AUTOSAR XML (schema 00049)
package /SwComponentTypes
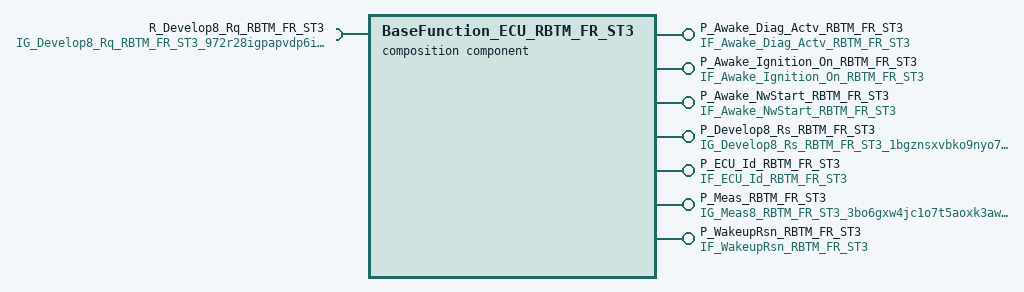
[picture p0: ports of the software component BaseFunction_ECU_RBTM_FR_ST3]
  composition sw component type BaseFunction_ECU_RBTM_FR_ST3  # Base Function
    7 x provide port:
      P_Awake_Diag_Actv_RBTM_FR_ST3: nonqueued-sender-com-spec{data-element=Awake_Diag_Actv_RBTM_FR_ST3, init-value=constant-reference=XDIS_h5tcyk98kzbgrc5svasomeyt}, provided-interface=IF_Awake_Diag_Actv_RBTM_FR_ST3  # Wachhalten für Diagnose aktiv / Stay awake for diagnostics active
      P_Awake_Ignition_On_RBTM_FR_ST3: nonqueued-sender-com-spec{data-element=Awake_Ignition_On_RBTM_FR_ST3, init-value=constant-reference=XDIS_h5tcyk98kzbgrc5svasomeyt}, provided-interface=IF_Awake_Ignition_On_RBTM_FR_ST3  # Wachhalten für Zündung eingeschaltet / Stay awake for ignition on
      P_Awake_NwStart_RBTM_FR_ST3: nonqueued-sender-com-spec{data-element=Awake_NwStart_RBTM_FR_ST3, init-value=constant-reference=XDIS_h5tcyk98kzbgrc5svasomeyt}, provided-interface=IF_Awake_NwStart_RBTM_FR_ST3  # Wachhalten für Netzwerkstartphase / Stay awake for network startup
      P_Develop8_Rs_RBTM_FR_ST3: nonqueued-sender-com-spec{data-element=Develop8_Rs_RBTM_FR_ST3, init-value=constant-reference=XDIS_7ll3jj0kzg4pxwvhz4t7z1xms}, provided-interface=IG_Develop8_Rs_RBTM_FR_ST3_1bgznsxvbko9nyo78yin9nalx  # Development Response (degraded)
      P_ECU_Id_RBTM_FR_ST3: nonqueued-sender-com-spec{data-element=ECU_Id_RBTM_FR_ST3, init-value=constant-reference=XDIS_2f2k10or7fzjcnsiqkruf2jdj}, provided-interface=IF_ECU_Id_RBTM_FR_ST3  # ECU-Identifizierungsnummer / ECU identifier
      P_Meas_RBTM_FR_ST3: nonqueued-sender-com-spec{data-element=Meas8_RBTM_FR_ST3, init-value=constant-reference=XDIS_byyw7b3ki3w79jkgp9jr5allr}, provided-interface=IG_Meas8_RBTM_FR_ST3_3bo6gxw4jc1o7t5aoxk3awdcy  # Messbotschaft (degraded) / Measurement (degraded)
      P_WakeupRsn_RBTM_FR_ST3: nonqueued-sender-com-spec{data-element=WakeupRsn_RBTM_FR_ST3, init-value=constant-reference=XDIS_3jaoqj7gfnekl0vo7yq70x2ub}, provided-interface=IF_WakeupRsn_RBTM_FR_ST3  # Weckgrund / Wakeup reason
    require port R_Develop8_Rq_RBTM_FR_ST3: nonqueued-receiver-com-spec{data-element=Develop8_Rq_RBTM_FR_ST3, reception-props=timeout=0, init-value=constant-reference=XDIS_6efbipe0xf9n4p1rmexr8mnnj}, required-interface=IG_Develop8_Rq_RBTM_FR_ST3_972r28igpapvdp6ireogwrkb1  # Development Request (degraded)
